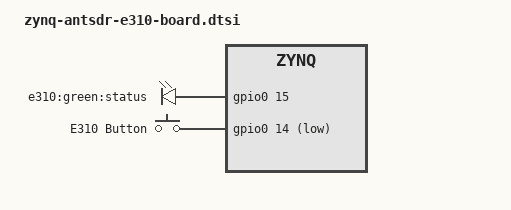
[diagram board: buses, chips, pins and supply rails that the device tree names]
// SPDX-License-Identifier: GPL-2.0-only
/* Shared ANTSDR E310 Rev.C board peripherals. */

#include <dt-bindings/input/input.h>

/ {
	leds {
		compatible = "gpio-leds";

		status_led: status {
			label = "e310:green:status";
			gpios = <&gpio0 15 GPIO_ACTIVE_HIGH>;
			linux,default-trigger = "heartbeat";
		};
	};

	gpio-keys {
		compatible = "gpio-keys";

		button {
			label = "E310 Button";
			linux,code = <BTN_MISC>;
			gpios = <&gpio0 14 GPIO_ACTIVE_LOW>;
		};
	};
};
